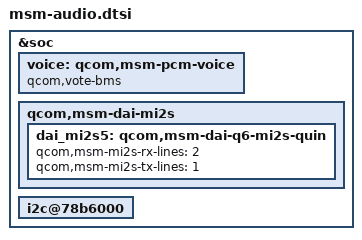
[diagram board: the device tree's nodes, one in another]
/*
 * Copyright (c) 2015-2016, The Linux Foundation. All rights reserved.
 *
 * This program is free software; you can redistribute it and/or modify
 * it under the terms of the GNU General Public License version 2 and
 * only version 2 as published by the Free Software Foundation.
 *
 * This program is distributed in the hope that it will be useful,
 * but WITHOUT ANY WARRANTY; without even the implied warranty of
 * MERCHANTABILITY or FITNESS FOR A PARTICULAR PURPOSE.  See the
 * GNU General Public License for more details.
 */

&soc {
	voice: qcom,msm-pcm-voice {
		qcom,vote-bms;
	};


	qcom,msm-dai-mi2s {
		dai_mi2s5: qcom,msm-dai-q6-mi2s-quin {
			qcom,msm-mi2s-rx-lines = <2>;
			qcom,msm-mi2s-tx-lines = <1>;
		};

	};


	i2c@78b6000 {
		/delete-node/ wsa881x-i2c-codec@e;
		/delete-node/ wsa881x-i2c-codec@44;
		/delete-node/ wsa881x-i2c-codec@f;
		/delete-node/ wsa881x-i2c-codec@45;
	};

};


